# tviic2d6m register map
Vendor: Infineon Technologies; Series: TVIIC2D6M; File version: 1.0
CPU: CM7 r0p1, little endian, MPU, FPU, double-precision FPU, I-cache, D-cache, VTOR, ITCM, DTCM, 3 interrupt priority bits, 16 interrupts
Registers are 32-bit, read-write, reset 0x0 unless marked. A register's access mark holds for its fields unless they carry their own. Offsets are from the block's base; lines under a group give offsets from that group; [hi:lo] are bit positions; {n}, {i} and the like mark numbered series; 'fields as' and 'values as' point back to an identical list; <NAME> marks a mode.

## Memory map
0x40000000 PERI size 0x10000 — Peripheral interconnect
0x40020000 PERI_MS size 0x20000 — Peripheral interconnect, master interface
0x40040000 PERI_PCLK size 0x20000 — Peripheral PCLK groups
0x40100000 CRYPTO size 0x10000 — Cryptography component
0x40200000 CPUSS size 0x10000 — CPU subsystem (CPUSS)
0x40210000 FAULT size 0x10000 — Fault structures
0x40220000 IPC size 0x10000
0x40230000 PROT size 0x10000 — Protection
0x40240000 FLASHC size 0x10000 — Flash controller
0x40260000 SRSS size 0x10000 — SRSS Core Registers (ver3p3)
0x40270000 BACKUP size 0x10000 — SRSS Backup Domain (ver3p3)
0x40280000 DW0 size 0x10000 — Datawire Controller
0x40290000 DW1 size 0x10000
0x402A0000 DMAC size 0x10000
0x402B0000 AXI_DMAC size 0x10000
0x402C0000 EFUSE size 0x200 — EFUSE MXS40 registers
0x40300000 HSIOM size 0x4000 — High Speed IO Matrix (HSIOM)
0x40310000 GPIO size 0x10000 — GPIO port control/configuration
0x40320000 SMARTIO size 0x10000 — Programmable IO configuration
0x40380000 TCPWM0 size 0x20000 — Timer/Counter/PWM
0x403F0000 EVTGEN0 size 0x1000 — Event generator
0x40400000 SMIF0 size 0x40000 — SMIF subsystem (bridge + 2 core SMIFs, OR no bridge and 1 core SMIF)
0x40480000 ETH0 size 0x10000 — Ethernet Interface
0x40500000 LIN0 size 0x10000 — LIN
0x40510000 CXPI0 size 0x10000 — CXPI
0x40520000 CANFD0 size 0x20000 — CAN Controller
0x40540000 CANFD1 size 0x20000
0x40600000 SCB0 size 0x10000 — Serial Communications Block (SPI/UART/I2C)
{0x40600000+0x10000*n} SCB{n} size 0x10000 (n=1..11)
0x40810000 TDM0 size 0x10000 — TDM
0x40820000 SG0 size 0x10000 — SG
0x40830000 PWM0 size 0x10000 — PWM
0x40840000 DAC0 size 0x100 — DAC
0x40880000 MIXER0 size 0x10000 — MIXER
0x40890000 MIXER1 size 0x10000
0x40900000 PASS0 size 0x100000 — Programmable Analog Subsystem for S40E

## Interrupts
{n} NvicMux{n} (CPUSS) (n=0..7) — CPU User Interrupt #{n}
{n+8} Internal{n} (CPUSS) (n=0..7) — Internal SW Interrupt #{n}

## HSIOM — High Speed IO Matrix (HSIOM)
Base 0x40300000
{0x0+0x10*i} PRT[{i}] (i=0..30) group — HSIOM port registers
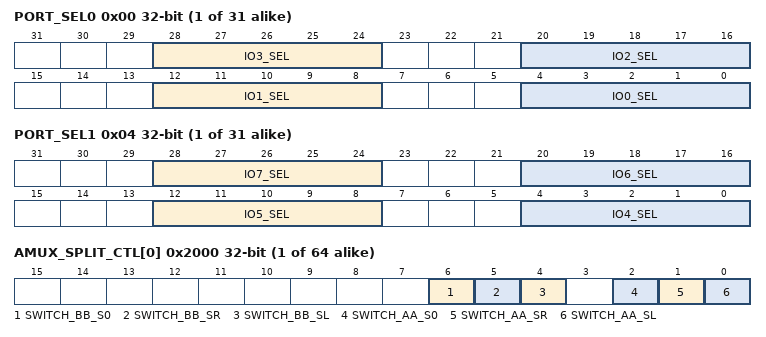
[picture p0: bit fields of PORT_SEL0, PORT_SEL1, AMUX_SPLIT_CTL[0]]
  0x00 PORT_SEL0 — Port selection 0
    [28:24] IO3_SEL — Selects the peripheral connections of Pin 3.
    [20:16] IO2_SEL — Selects the peripheral connections of Pin 2.
    [12:8] IO1_SEL — Selects the peripheral connections of Pin 1.
    [4:0] IO0_SEL — Selects the peripheral connections of Pin 0. Note that available connectivity options vary depending on the device, port and the pin. See the device Datasheet for a list of peripheral connections available at each pin.
      0=GPIO (GPIO controls 'out'); 1=GPIO_DSI (GPIO controls 'out', DSI controls 'output enable'); 2=DSI_DSI (DSI controls 'out' and 'output enable'); 3=DSI_GPIO (DSI controls 'out', GPIO controls 'output enable'); 4=AMUXA (Analog mux bus A); 5=AMUXB (Analog mux bus B); 6=AMUXA_DSI (Analog mux bus A, DSI control); 7=AMUXB_DSI (Analog mux bus B, DSI control); {v}=ACT_{v-8} (Active functionality {v-8}) (v=8..11); {v}=DS_{v-12} (DeepSleep functionality {v-12}) (v=12..15); {v}=ACT_{v-12} (Active functionality {v-12}) (v=16..27); {v}=DS_{v-24} (DeepSleep functionality {v-24}) (v=28..31)
  0x04 PORT_SEL1 — Port selection 1
    [28:24] IO7_SEL — Selects the peripheral connections of Pin 6.
    [20:16] IO6_SEL — Selects the peripheral connections of Pin 5.
    [12:8] IO5_SEL — Selects the peripheral connections of Pin 4.
    [4:0] IO4_SEL — Selects the peripheral connections of Pin 4. See PORT_SEL0 for connection details.
{0x2000+4i} AMUX_SPLIT_CTL[{i}] (i=0..63) — AMUX splitter cell control
  [6] SWITCH_BB_S0 — T-switch control for AMUXBUSB vssa/ground switch.
  [5] SWITCH_BB_SR — T-switch control for Right AMUXBUSB switch.
  [4] SWITCH_BB_SL — T-switch control for Left AMUXBUSB switch.
  [2] SWITCH_AA_S0 — T-switch control for AMUXBUSA vssa/ground switch: '0': switch open. '1': switch closed.
  [1] SWITCH_AA_SR — T-switch control for Right AMUXBUSA switch: '0': switch open. '1': switch closed.
  [0] SWITCH_AA_SL — T-switch control for Left AMUXBUSA switch: '0': switch open. '1': switch closed.
{0x2200+4i} MONITOR_CTL_{i} (i=0..3) — Power/Ground Monitor cell control {i}
  [31:0] MONITOR_EN — control for switch, which connects the power/ground supply to AMUXBUS_A/B respectively when switch is closed: '0': switch open. '1': switch closed.
0x2240 ALT_JTAG_EN — Alternate JTAG IF selection register
  [31] ENABLE — Provides the selection for alternate JTAG IF connectivity. 0: Primary JTAG interface is selected 1: Secondary (alternate) JTAG interface is selected. This connectivity works ONLY in ACTIVE mode.

## Licence text in the file
(c) (2016-2026), Infineon Technologies AG or an affiliate of Infineon Technologies AG. . SPDX-License-Identifier: Apache-2.0 . Licensed under the Apache License, Version 2.0 (the "License"); you may not use this file except in compliance with the License. You may obtain a copy of the License at http://www.apache.org/licenses/LICENSE-2.0 . Unless required by applicable law or agreed to in writing, software distributed under the License is distributed on an "AS IS" BASIS, WITHOUT WARRANTIES OR CONDITIONS OF ANY KIND, either express or implied. See the License for the specific language governing permissions and limitations under the License.
